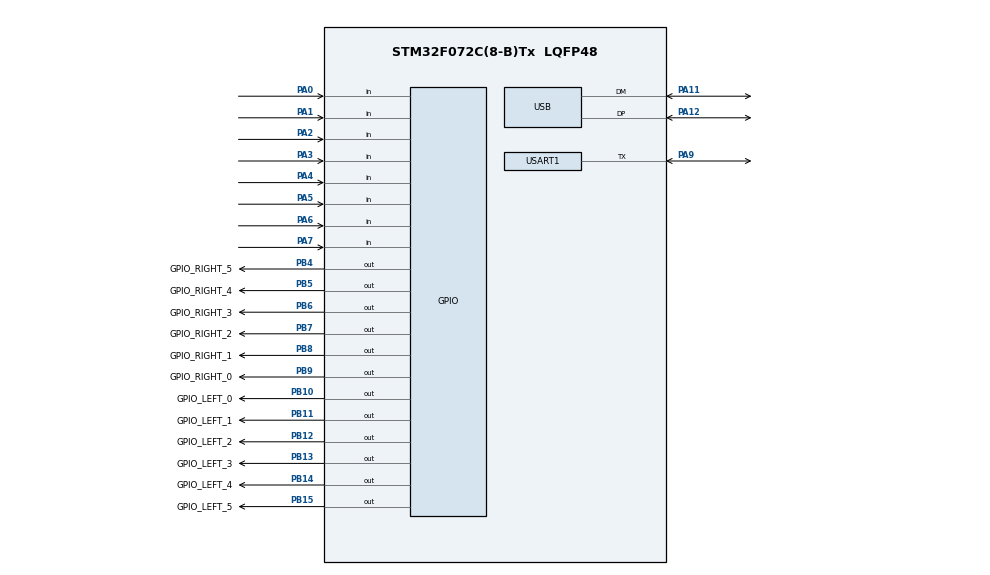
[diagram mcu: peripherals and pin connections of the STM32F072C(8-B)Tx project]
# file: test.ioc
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CRC.InputDataFormat=CRC_INPUTDATA_FORMAT_BYTES
Dma.Request0=USART1_TX
Dma.Request1=USART1_RX
Dma.USART1_RX.1.Direction=DMA_PERIPH_TO_MEMORY
Dma.USART1_RX.1.Instance=DMA1_Channel3
Dma.USART1_RX.1.MemDataAlignment=DMA_MDATAALIGN_BYTE
Dma.USART1_RX.1.MemInc=DMA_MINC_ENABLE
Dma.USART1_RX.1.Mode=DMA_NORMAL
Dma.USART1_RX.1.PeriphDataAlignment=DMA_PDATAALIGN_BYTE
Dma.USART1_RX.1.PeriphInc=DMA_PINC_DISABLE
Dma.USART1_RX.1.Priority=DMA_PRIORITY_VERY_HIGH
Dma.USART1_TX.0.Direction=DMA_MEMORY_TO_PERIPH
Dma.USART1_TX.0.Instance=DMA1_Channel4
Dma.USART1_TX.0.MemDataAlignment=DMA_MDATAALIGN_BYTE
Dma.USART1_TX.0.MemInc=DMA_MINC_ENABLE
Dma.USART1_TX.0.Mode=DMA_NORMAL
Dma.USART1_TX.0.PeriphDataAlignment=DMA_PDATAALIGN_BYTE
Dma.USART1_TX.0.PeriphInc=DMA_PINC_DISABLE
Dma.USART1_TX.0.Priority=DMA_PRIORITY_HIGH
Mcu.Family=STM32F0
Mcu.Name=STM32F072C(8-B)Tx
Mcu.Package=LQFP48
NVIC.DMA1_Channel2_3_IRQn=true\:0\:0\:false\:false\:true\:false\:true
NVIC.DMA1_Channel4_5_6_7_IRQn=true\:0\:0\:false\:false\:true\:false\:true
NVIC.TIM15_IRQn=true\:0\:0\:false\:false\:false\:true\:false
NVIC.TIM16_IRQn=true\:0\:0\:false\:false\:false\:true\:false
NVIC.TIM17_IRQn=true\:0\:0\:false\:false\:false\:true\:false
NVIC.TIM6_DAC_IRQn=true\:0\:0\:false\:false\:false\:true\:false
NVIC.TIM7_IRQn=true\:0\:0\:false\:false\:false\:true\:false
NVIC.USART1_IRQn=true\:0\:0\:false\:false\:true\:true\:true
NVIC.USB_IRQn=true\:0\:0\:false\:false\:true\:false\:true
PA0.GPIO_PuPd=GPIO_PULLDOWN
PA0.Signal=GPIO_Input
PA1.GPIO_PuPd=GPIO_PULLDOWN
PA1.Signal=GPIO_Input
PA11.Mode=Device
PA11.Signal=USB_DM
PA12.Mode=Device
PA12.Signal=USB_DP
PA13.Mode=Serial_Wire
PA13.Signal=SYS_SWDIO
PA14.Mode=Serial_Wire
PA14.Signal=SYS_SWCLK
PA2.GPIO_PuPd=GPIO_PULLDOWN
PA2.Signal=GPIO_Input
PA3.GPIO_PuPd=GPIO_PULLDOWN
PA3.Signal=GPIO_Input
PA4.GPIO_PuPd=GPIO_PULLDOWN
PA4.Signal=GPIO_Input
PA5.GPIO_PuPd=GPIO_PULLDOWN
PA5.Signal=GPIO_Input
PA6.GPIO_PuPd=GPIO_PULLDOWN
PA6.Signal=GPIO_Input
PA7.GPIO_PuPd=GPIO_PULLDOWN
PA7.Signal=GPIO_Input
PA9.GPIO_ModeDefaultOD=GPIO_MODE_AF_OD
PA9.GPIO_PuPdOD=GPIO_NOPULL
PA9.GPIO_Speed=GPIO_SPEED_FREQ_LOW
PA9.Mode=Half_duplex(single_wire_mode)
PA9.Signal=USART1_TX
PB10.GPIO_Label=GPIO_LEFT_0
PB10.GPIO_ModeDefaultOutputPP=GPIO_MODE_OUTPUT_PP
PB10.GPIO_Speed=GPIO_SPEED_FREQ_LOW
PB10.Signal=GPIO_Output
PB11.GPIO_Label=GPIO_LEFT_1
PB11.GPIO_ModeDefaultOutputPP=GPIO_MODE_OUTPUT_PP
PB11.GPIO_Speed=GPIO_SPEED_FREQ_LOW
PB11.Signal=GPIO_Output
PB12.GPIO_Label=GPIO_LEFT_2
PB12.GPIO_ModeDefaultOutputPP=GPIO_MODE_OUTPUT_PP
PB12.GPIO_Speed=GPIO_SPEED_FREQ_LOW
PB12.Signal=GPIO_Output
PB13.GPIO_Label=GPIO_LEFT_3
PB13.GPIO_ModeDefaultOutputPP=GPIO_MODE_OUTPUT_PP
PB13.GPIO_Speed=GPIO_SPEED_FREQ_LOW
PB13.Signal=GPIO_Output
PB14.GPIO_Label=GPIO_LEFT_4
PB14.GPIO_ModeDefaultOutputPP=GPIO_MODE_OUTPUT_PP
PB14.GPIO_Speed=GPIO_SPEED_FREQ_LOW
PB14.Signal=GPIO_Output
PB15.GPIO_Label=GPIO_LEFT_5
PB15.GPIO_ModeDefaultOutputPP=GPIO_MODE_OUTPUT_PP
PB15.GPIO_Speed=GPIO_SPEED_FREQ_LOW
PB15.Signal=GPIO_Output
PB4.GPIO_Label=GPIO_RIGHT_5
PB4.GPIO_Speed=GPIO_SPEED_FREQ_LOW
PB4.Signal=GPIO_Output
PB5.GPIO_Label=GPIO_RIGHT_4
PB5.GPIO_Speed=GPIO_SPEED_FREQ_LOW
PB5.Signal=GPIO_Output
PB6.GPIO_Label=GPIO_RIGHT_3
PB6.GPIO_Speed=GPIO_SPEED_FREQ_LOW
PB6.Signal=GPIO_Output
PB7.GPIO_Label=GPIO_RIGHT_2
PB7.GPIO_Speed=GPIO_SPEED_FREQ_LOW
PB7.Signal=GPIO_Output
PB8.GPIO_Label=GPIO_RIGHT_1
PB8.GPIO_Speed=GPIO_SPEED_FREQ_LOW
PB8.Signal=GPIO_Output
PB9.GPIO_Label=GPIO_RIGHT_0
PB9.GPIO_Speed=GPIO_SPEED_FREQ_LOW
PB9.Signal=GPIO_Output
ProjectManager.HeapSize=0x200
ProjectManager.StackSize=0x400
ProjectManager.TargetToolchain=Makefile
RCC.AHBFreq_Value=16000000
RCC.APB1Freq_Value=16000000
RCC.APB1TimFreq_Value=16000000
RCC.HCLKFreq_Value=16000000
RCC.HSI48CalibrationValue=32
RCC.PLLDivider=RCC_PREDIV_DIV6
RCC.PLLSourceVirtual=RCC_PLLSOURCE_HSI48
RCC.RCC_MCOSource=RCC_MCO1SOURCE_HSI48
RCC.SYSCLKFreq_VALUE=16000000
RCC.SYSCLKSource=RCC_SYSCLKSOURCE_PLLCLK
TIM15.Period=500
TIM15.Prescaler=15999
TIM16.Period=99
TIM16.Prescaler=15999
TIM17.Period=500
TIM17.Prescaler=15999
TIM6.Period=500
TIM6.Prescaler=15
TIM6.TIM_MasterOutputTrigger=TIM_TRGO_RESET
TIM7.Period=9
TIM7.Prescaler=15999
USART1.AutoBaudRateEnableParam=UART_ADVFEATURE_AUTOBAUDRATE_DISABLE
USART1.BaudRate=1000000
USART1.DMADisableonRxErrorParam=ADVFEATURE_DMA_ENABLEONRXERROR
USART1.Mode=MODE_TX_RX
USART1.OverSampling=UART_OVERSAMPLING_16
USART1.OverrunDisableParam=ADVFEATURE_OVERRUN_ENABLE
USART1.SwapParam=ADVFEATURE_SWAP_DISABLE
USART1.VirtualMode-Half_duplex(single_wire_mode)=VM_ASYNC
USB.low_power_enable=DISABLE
USB.lpm_enable=ENABLE
USB_DEVICE.CLASS_NAME_FS=CUSTOM_HID
USB_DEVICE.CUSTOM_HID_FS_BINTERVAL=0x1
USB_DEVICE.MANUFACTURER_STRING=bareminimum
USB_DEVICE.PRODUCT_STRING_CUSTOMHID_FS=bareminimum keys
USB_DEVICE.USBD_CUSTOMHID_OUTREPORT_BUF_SIZE=8
USB_DEVICE.USBD_CUSTOM_HID_REPORT_DESC_SIZE=41
USB_DEVICE.USBD_SELF_POWERED=0
USB_DEVICE.VirtualMode=CustomHid
USB_DEVICE.VirtualModeFS=Custom_Hid_FS
VP_CRC_VS_CRC.Mode=CRC_Activate
VP_RCC_USB.Mode=CRS SYNC Source USB
VP_TIM15_VS_OPM.Mode=OPM_bit
VP_TIM16_VS_ClockSourceINT.Mode=Enable_Timer
VP_TIM16_VS_OPM.Mode=OPM_bit
VP_TIM17_VS_ClockSourceINT.Mode=Enable_Timer
VP_TIM17_VS_OPM.Mode=OPM_bit
VP_TIM6_VS_ClockSourceINT.Mode=Enable_Timer
VP_TIM6_VS_OPM.Mode=OPM_bit
VP_TIM7_VS_ClockSourceINT.Mode=Enable_Timer
VP_TIM7_VS_OPM.Mode=OPM_bit
VP_USB_DEVICE_VS_USB_DEVICE_CUSTOM_HID_FS.Mode=CUSTOM_HID_FS
board=custom

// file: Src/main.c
/* USER CODE BEGIN Header */
/**
  ******************************************************************************
  * @file           : main.c
  * @brief          : Main program body
  ******************************************************************************
  * @attention
  *
  * <h2><center>&copy; Copyright (c) 2020 STMicroelectronics.
  * All rights reserved.</center></h2>
  *
  * This software component is licensed by ST under Ultimate Liberty license
  * SLA0044, the "License"; You may not use this file except in compliance with
  * the License. You may obtain a copy of the License at:
  *                             www.st.com/SLA0044
  *
  ******************************************************************************
  */
/* USER CODE END Header */

#include "main.h"
#include "usb_device.h"

/* USER CODE BEGIN Includes */

#include "app.h"

/* USER CODE END Includes */

UART_HandleTypeDef huart1;
DMA_HandleTypeDef hdma_usart1_tx;
DMA_HandleTypeDef hdma_usart1_rx;

void SystemClock_Config(void);
static void MX_GPIO_Init(void);
static void MX_DMA_Init(void);
static void MX_USART1_UART_Init(void);
static void MX_TIM6_Init(void);
static void MX_TIM7_Init(void);
static void MX_TIM16_Init(void);
static void MX_TIM17_Init(void);
static void MX_CRC_Init(void);
static void MX_TIM15_Init(void);

int main(void)
{

  /* MCU Configuration--------------------------------------------------------*/

  /* Reset of all peripherals, Initializes the Flash interface and the Systick. */
  HAL_Init();

  /* Configure the system clock */
  SystemClock_Config();

  /* Initialize all configured peripherals */
  MX_GPIO_Init();
  MX_DMA_Init();
  MX_USART1_UART_Init();
  MX_USB_DEVICE_Init();
  MX_TIM6_Init();
  MX_TIM7_Init();
  MX_TIM16_Init();
  MX_TIM17_Init();
  MX_CRC_Init();
  MX_TIM15_Init();
  /* USER CODE BEGIN 2 */
  app();
  /* USER CODE END 2 */

  /* Infinite loop */
  while (1)
  {

  }
}

void SystemClock_Config(void)
{
  LL_FLASH_SetLatency(LL_FLASH_LATENCY_0);

  if(LL_FLASH_GetLatency() != LL_FLASH_LATENCY_0)
  {
  Error_Handler();
  }
  LL_RCC_HSI48_Enable();

   /* Wait till HSI48 is ready */
  while(LL_RCC_HSI48_IsReady() != 1)
  {

  }
  LL_RCC_PLL_ConfigDomain_SYS(LL_RCC_PLLSOURCE_HSI48, LL_RCC_PLL_MUL_2, LL_RCC_PREDIV_DIV_6);
  LL_RCC_PLL_Enable();

   /* Wait till PLL is ready */
  while(LL_RCC_PLL_IsReady() != 1)
  {

  }
  LL_RCC_SetAHBPrescaler(LL_RCC_SYSCLK_DIV_1);
  LL_RCC_SetAPB1Prescaler(LL_RCC_APB1_DIV_1);
  LL_RCC_SetSysClkSource(LL_RCC_SYS_CLKSOURCE_PLL);

   /* Wait till System clock is ready */
  while(LL_RCC_GetSysClkSource() != LL_RCC_SYS_CLKSOURCE_STATUS_PLL)
  {

  }
  LL_SetSystemCoreClock(16000000);

   /* Update the time base */
  if (HAL_InitTick (TICK_INT_PRIORITY) != HAL_OK)
  {
    Error_Handler();
  };
  LL_RCC_SetUSARTClockSource(LL_RCC_USART1_CLKSOURCE_PCLK1);
  LL_RCC_SetUSBClockSource(LL_RCC_USB_CLKSOURCE_HSI48);
  LL_CRS_SetSyncDivider(LL_CRS_SYNC_DIV_1);
  LL_CRS_SetSyncPolarity(LL_CRS_SYNC_POLARITY_RISING);
  LL_CRS_SetSyncSignalSource(LL_CRS_SYNC_SOURCE_USB);
  LL_CRS_SetFreqErrorLimit(34);
  LL_CRS_SetHSI48SmoothTrimming(32);
}

static void MX_CRC_Init(void)
{

  /* Peripheral clock enable */
  LL_AHB1_GRP1_EnableClock(LL_AHB1_GRP1_PERIPH_CRC);

  LL_CRC_SetInputDataReverseMode(CRC, LL_CRC_INDATA_REVERSE_NONE);
  LL_CRC_SetOutputDataReverseMode(CRC, LL_CRC_OUTDATA_REVERSE_NONE);
  LL_CRC_SetInitialData(CRC, LL_CRC_DEFAULT_CRC_INITVALUE);

}

static void MX_TIM6_Init(void)
{

  LL_TIM_InitTypeDef TIM_InitStruct = {0};

  /* Peripheral clock enable */
  LL_APB1_GRP1_EnableClock(LL_APB1_GRP1_PERIPH_TIM6);

  /* TIM6 interrupt Init */
  NVIC_SetPriority(TIM6_DAC_IRQn, 0);
  NVIC_EnableIRQ(TIM6_DAC_IRQn);

  TIM_InitStruct.Prescaler = 15;
  TIM_InitStruct.CounterMode = LL_TIM_COUNTERMODE_UP;
  TIM_InitStruct.Autoreload = 500;
  LL_TIM_Init(TIM6, &TIM_InitStruct);
  LL_TIM_DisableARRPreload(TIM6);
  LL_TIM_SetOnePulseMode(TIM6, LL_TIM_ONEPULSEMODE_SINGLE);
  LL_TIM_SetTriggerOutput(TIM6, LL_TIM_TRGO_RESET);
  LL_TIM_DisableMasterSlaveMode(TIM6);

}

static void MX_TIM7_Init(void)
{

  LL_TIM_InitTypeDef TIM_InitStruct = {0};

  /* Peripheral clock enable */
  LL_APB1_GRP1_EnableClock(LL_APB1_GRP1_PERIPH_TIM7);

  /* TIM7 interrupt Init */
  NVIC_SetPriority(TIM7_IRQn, 0);
  NVIC_EnableIRQ(TIM7_IRQn);

  TIM_InitStruct.Prescaler = 15999;
  TIM_InitStruct.CounterMode = LL_TIM_COUNTERMODE_UP;
  TIM_InitStruct.Autoreload = 9;
  LL_TIM_Init(TIM7, &TIM_InitStruct);
  LL_TIM_DisableARRPreload(TIM7);
  LL_TIM_SetOnePulseMode(TIM7, LL_TIM_ONEPULSEMODE_SINGLE);
  LL_TIM_SetTriggerOutput(TIM7, LL_TIM_TRGO_RESET);
  LL_TIM_DisableMasterSlaveMode(TIM7);

}

static void MX_TIM15_Init(void)
{

  LL_TIM_InitTypeDef TIM_InitStruct = {0};

  /* Peripheral clock enable */
  LL_APB1_GRP2_EnableClock(LL_APB1_GRP2_PERIPH_TIM15);

  /* TIM15 interrupt Init */
  NVIC_SetPriority(TIM15_IRQn, 0);
  NVIC_EnableIRQ(TIM15_IRQn);

  TIM_InitStruct.Prescaler = 15999;
  TIM_InitStruct.CounterMode = LL_TIM_COUNTERMODE_UP;
  TIM_InitStruct.Autoreload = 500;
  TIM_InitStruct.ClockDivision = LL_TIM_CLOCKDIVISION_DIV1;
  TIM_InitStruct.RepetitionCounter = 0;
  LL_TIM_Init(TIM15, &TIM_InitStruct);
  LL_TIM_DisableARRPreload(TIM15);
  LL_TIM_SetOnePulseMode(TIM15, LL_TIM_ONEPULSEMODE_SINGLE);

}

static void MX_TIM16_Init(void)
{

  LL_TIM_InitTypeDef TIM_InitStruct = {0};

  /* Peripheral clock enable */
  LL_APB1_GRP2_EnableClock(LL_APB1_GRP2_PERIPH_TIM16);

  /* TIM16 interrupt Init */
  NVIC_SetPriority(TIM16_IRQn, 0);
  NVIC_EnableIRQ(TIM16_IRQn);

  TIM_InitStruct.Prescaler = 15999;
  TIM_InitStruct.CounterMode = LL_TIM_COUNTERMODE_UP;
  TIM_InitStruct.Autoreload = 99;
  TIM_InitStruct.ClockDivision = LL_TIM_CLOCKDIVISION_DIV1;
  TIM_InitStruct.RepetitionCounter = 0;
  LL_TIM_Init(TIM16, &TIM_InitStruct);
  LL_TIM_DisableARRPreload(TIM16);
  LL_TIM_SetOnePulseMode(TIM16, LL_TIM_ONEPULSEMODE_SINGLE);

}

static void MX_TIM17_Init(void)
{

  LL_TIM_InitTypeDef TIM_InitStruct = {0};

  /* Peripheral clock enable */
  LL_APB1_GRP2_EnableClock(LL_APB1_GRP2_PERIPH_TIM17);

  /* TIM17 interrupt Init */
  NVIC_SetPriority(TIM17_IRQn, 0);
  NVIC_EnableIRQ(TIM17_IRQn);

  TIM_InitStruct.Prescaler = 15999;
  TIM_InitStruct.CounterMode = LL_TIM_COUNTERMODE_UP;
  TIM_InitStruct.Autoreload = 500;
  TIM_InitStruct.ClockDivision = LL_TIM_CLOCKDIVISION_DIV1;
  TIM_InitStruct.RepetitionCounter = 0;
  LL_TIM_Init(TIM17, &TIM_InitStruct);
  LL_TIM_DisableARRPreload(TIM17);
  LL_TIM_SetOnePulseMode(TIM17, LL_TIM_ONEPULSEMODE_SINGLE);

}

static void MX_USART1_UART_Init(void)
{

  huart1.Instance = USART1;
  huart1.Init.BaudRate = 1000000;
  huart1.Init.WordLength = UART_WORDLENGTH_8B;
  huart1.Init.StopBits = UART_STOPBITS_1;
  huart1.Init.Parity = UART_PARITY_NONE;
  huart1.Init.Mode = UART_MODE_TX_RX;
  huart1.Init.HwFlowCtl = UART_HWCONTROL_NONE;
  huart1.Init.OverSampling = UART_OVERSAMPLING_16;
  huart1.Init.OneBitSampling = UART_ONE_BIT_SAMPLE_DISABLE;
  huart1.AdvancedInit.AdvFeatureInit = UART_ADVFEATURE_NO_INIT;
  if (HAL_HalfDuplex_Init(&huart1) != HAL_OK)
  {
    Error_Handler();
  }

}

static void MX_DMA_Init(void)
{

  /* Init with LL driver */
  /* DMA controller clock enable */
  LL_AHB1_GRP1_EnableClock(LL_AHB1_GRP1_PERIPH_DMA1);

  /* DMA interrupt init */
  /* DMA1_Channel2_3_IRQn interrupt configuration */
  HAL_NVIC_SetPriority(DMA1_Channel2_3_IRQn, 0, 0);
  HAL_NVIC_EnableIRQ(DMA1_Channel2_3_IRQn);
  /* DMA1_Channel4_5_6_7_IRQn interrupt configuration */
  HAL_NVIC_SetPriority(DMA1_Channel4_5_6_7_IRQn, 0, 0);
  HAL_NVIC_EnableIRQ(DMA1_Channel4_5_6_7_IRQn);

}

static void MX_GPIO_Init(void)
{
  LL_GPIO_InitTypeDef GPIO_InitStruct = {0};

  /* GPIO Ports Clock Enable */
  LL_AHB1_GRP1_EnableClock(LL_AHB1_GRP1_PERIPH_GPIOC);
  LL_AHB1_GRP1_EnableClock(LL_AHB1_GRP1_PERIPH_GPIOF);
  LL_AHB1_GRP1_EnableClock(LL_AHB1_GRP1_PERIPH_GPIOA);
  LL_AHB1_GRP1_EnableClock(LL_AHB1_GRP1_PERIPH_GPIOB);

  /**/
  LL_GPIO_ResetOutputPin(GPIO_LEFT_0_GPIO_Port, GPIO_LEFT_0_Pin);

  /**/
  LL_GPIO_ResetOutputPin(GPIO_LEFT_1_GPIO_Port, GPIO_LEFT_1_Pin);

  /**/
  LL_GPIO_ResetOutputPin(GPIO_LEFT_2_GPIO_Port, GPIO_LEFT_2_Pin);

  /**/
  LL_GPIO_ResetOutputPin(GPIO_LEFT_3_GPIO_Port, GPIO_LEFT_3_Pin);

  /**/
  LL_GPIO_ResetOutputPin(GPIO_LEFT_4_GPIO_Port, GPIO_LEFT_4_Pin);

  /**/
  LL_GPIO_ResetOutputPin(GPIO_LEFT_5_GPIO_Port, GPIO_LEFT_5_Pin);

  /**/
  LL_GPIO_ResetOutputPin(GPIO_RIGHT_5_GPIO_Port, GPIO_RIGHT_5_Pin);

  /**/
  LL_GPIO_ResetOutputPin(GPIO_RIGHT_4_GPIO_Port, GPIO_RIGHT_4_Pin);

  /**/
  LL_GPIO_ResetOutputPin(GPIO_RIGHT_3_GPIO_Port, GPIO_RIGHT_3_Pin);

  /**/
  LL_GPIO_ResetOutputPin(GPIO_RIGHT_2_GPIO_Port, GPIO_RIGHT_2_Pin);

  /**/
  LL_GPIO_ResetOutputPin(GPIO_RIGHT_1_GPIO_Port, GPIO_RIGHT_1_Pin);

  /**/
  LL_GPIO_ResetOutputPin(GPIO_RIGHT_0_GPIO_Port, GPIO_RIGHT_0_Pin);

  /**/
  GPIO_InitStruct.Pin = LL_GPIO_PIN_13;
  GPIO_InitStruct.Mode = LL_GPIO_MODE_ANALOG;
  GPIO_InitStruct.Pull = LL_GPIO_PULL_NO;
  LL_GPIO_Init(GPIOC, &GPIO_InitStruct);

  /**/
  GPIO_InitStruct.Pin = LL_GPIO_PIN_14;
  GPIO_InitStruct.Mode = LL_GPIO_MODE_ANALOG;
  GPIO_InitStruct.Pull = LL_GPIO_PULL_NO;
  LL_GPIO_Init(GPIOC, &GPIO_InitStruct);

  /**/
  GPIO_InitStruct.Pin = LL_GPIO_PIN_15;
  GPIO_InitStruct.Mode = LL_GPIO_MODE_ANALOG;
  GPIO_InitStruct.Pull = LL_GPIO_PULL_NO;
  LL_GPIO_Init(GPIOC, &GPIO_InitStruct);

  /**/
  GPIO_InitStruct.Pin = LL_GPIO_PIN_0;
  GPIO_InitStruct.Mode = LL_GPIO_MODE_ANALOG;
  GPIO_InitStruct.Pull = LL_GPIO_PULL_NO;
  LL_GPIO_Init(GPIOF, &GPIO_InitStruct);

  /**/
  GPIO_InitStruct.Pin = LL_GPIO_PIN_1;
  GPIO_InitStruct.Mode = LL_GPIO_MODE_ANALOG;
  GPIO_InitStruct.Pull = LL_GPIO_PULL_NO;
  LL_GPIO_Init(GPIOF, &GPIO_InitStruct);

  /**/
  GPIO_InitStruct.Pin = LL_GPIO_PIN_0;
  GPIO_InitStruct.Mode = LL_GPIO_MODE_INPUT;
  GPIO_InitStruct.Pull = LL_GPIO_PULL_DOWN;
  LL_GPIO_Init(GPIOA, &GPIO_InitStruct);

  /**/
  GPIO_InitStruct.Pin = LL_GPIO_PIN_1;
  GPIO_InitStruct.Mode = LL_GPIO_MODE_INPUT;
  GPIO_InitStruct.Pull = LL_GPIO_PULL_DOWN;
  LL_GPIO_Init(GPIOA, &GPIO_InitStruct);

  /**/
  GPIO_InitStruct.Pin = LL_GPIO_PIN_2;
  GPIO_InitStruct.Mode = LL_GPIO_MODE_INPUT;
  GPIO_InitStruct.Pull = LL_GPIO_PULL_DOWN;
  LL_GPIO_Init(GPIOA, &GPIO_InitStruct);

  /**/
  GPIO_InitStruct.Pin = LL_GPIO_PIN_3;
  GPIO_InitStruct.Mode = LL_GPIO_MODE_INPUT;
  GPIO_InitStruct.Pull = LL_GPIO_PULL_DOWN;
  LL_GPIO_Init(GPIOA, &GPIO_InitStruct);

  /**/
  GPIO_InitStruct.Pin = LL_GPIO_PIN_4;
  GPIO_InitStruct.Mode = LL_GPIO_MODE_INPUT;
  GPIO_InitStruct.Pull = LL_GPIO_PULL_DOWN;
  LL_GPIO_Init(GPIOA, &GPIO_InitStruct);

  /**/
  GPIO_InitStruct.Pin = LL_GPIO_PIN_5;
  GPIO_InitStruct.Mode = LL_GPIO_MODE_INPUT;
  GPIO_InitStruct.Pull = LL_GPIO_PULL_DOWN;
  LL_GPIO_Init(GPIOA, &GPIO_InitStruct);

  /**/
  GPIO_InitStruct.Pin = LL_GPIO_PIN_6;
  GPIO_InitStruct.Mode = LL_GPIO_MODE_INPUT;
  GPIO_InitStruct.Pull = LL_GPIO_PULL_DOWN;
  LL_GPIO_Init(GPIOA, &GPIO_InitStruct);

  /**/
  GPIO_InitStruct.Pin = LL_GPIO_PIN_7;
  GPIO_InitStruct.Mode = LL_GPIO_MODE_INPUT;
  GPIO_InitStruct.Pull = LL_GPIO_PULL_DOWN;
  LL_GPIO_Init(GPIOA, &GPIO_InitStruct);

  /**/
  GPIO_InitStruct.Pin = LL_GPIO_PIN_0;
  GPIO_InitStruct.Mode = LL_GPIO_MODE_ANALOG;
  GPIO_InitStruct.Pull = LL_GPIO_PULL_NO;
  LL_GPIO_Init(GPIOB, &GPIO_InitStruct);

  /**/
  GPIO_InitStruct.Pin = LL_GPIO_PIN_1;
  GPIO_InitStruct.Mode = LL_GPIO_MODE_ANALOG;
  GPIO_InitStruct.Pull = LL_GPIO_PULL_NO;
  LL_GPIO_Init(GPIOB, &GPIO_InitStruct);

  /**/
  GPIO_InitStruct.Pin = LL_GPIO_PIN_2;
  GPIO_InitStruct.Mode = LL_GPIO_MODE_ANALOG;
  GPIO_InitStruct.Pull = LL_GPIO_PULL_NO;
  LL_GPIO_Init(GPIOB, &GPIO_InitStruct);

  /**/
  GPIO_InitStruct.Pin = GPIO_LEFT_0_Pin;
  GPIO_InitStruct.Mode = LL_GPIO_MODE_OUTPUT;
  GPIO_InitStruct.Speed = LL_GPIO_SPEED_FREQ_LOW;
  GPIO_InitStruct.OutputType = LL_GPIO_OUTPUT_PUSHPULL;
  GPIO_InitStruct.Pull = LL_GPIO_PULL_NO;
  LL_GPIO_Init(GPIO_LEFT_0_GPIO_Port, &GPIO_InitStruct);

  /**/
  GPIO_InitStruct.Pin = GPIO_LEFT_1_Pin;
  GPIO_InitStruct.Mode = LL_GPIO_MODE_OUTPUT;
  GPIO_InitStruct.Speed = LL_GPIO_SPEED_FREQ_LOW;
  GPIO_InitStruct.OutputType = LL_GPIO_OUTPUT_PUSHPULL;
  GPIO_InitStruct.Pull = LL_GPIO_PULL_NO;
  LL_GPIO_Init(GPIO_LEFT_1_GPIO_Port, &GPIO_InitStruct);

  /**/
  GPIO_InitStruct.Pin = GPIO_LEFT_2_Pin;
  GPIO_InitStruct.Mode = LL_GPIO_MODE_OUTPUT;
  GPIO_InitStruct.Speed = LL_GPIO_SPEED_FREQ_LOW;
  GPIO_InitStruct.OutputType = LL_GPIO_OUTPUT_PUSHPULL;
  GPIO_InitStruct.Pull = LL_GPIO_PULL_NO;
  LL_GPIO_Init(GPIO_LEFT_2_GPIO_Port, &GPIO_InitStruct);

  /**/
  GPIO_InitStruct.Pin = GPIO_LEFT_3_Pin;
  GPIO_InitStruct.Mode = LL_GPIO_MODE_OUTPUT;
  GPIO_InitStruct.Speed = LL_GPIO_SPEED_FREQ_LOW;
  GPIO_InitStruct.OutputType = LL_GPIO_OUTPUT_PUSHPULL;
  GPIO_InitStruct.Pull = LL_GPIO_PULL_NO;
  LL_GPIO_Init(GPIO_LEFT_3_GPIO_Port, &GPIO_InitStruct);

  /**/
  GPIO_InitStruct.Pin = GPIO_LEFT_4_Pin;
  GPIO_InitStruct.Mode = LL_GPIO_MODE_OUTPUT;
  GPIO_InitStruct.Speed = LL_GPIO_SPEED_FREQ_LOW;
  GPIO_InitStruct.OutputType = LL_GPIO_OUTPUT_PUSHPULL;
  GPIO_InitStruct.Pull = LL_GPIO_PULL_NO;
  LL_GPIO_Init(GPIO_LEFT_4_GPIO_Port, &GPIO_InitStruct);

  /**/
  GPIO_InitStruct.Pin = GPIO_LEFT_5_Pin;
  GPIO_InitStruct.Mode = LL_GPIO_MODE_OUTPUT;
  GPIO_InitStruct.Speed = LL_GPIO_SPEED_FREQ_LOW;
  GPIO_InitStruct.OutputType = LL_GPIO_OUTPUT_PUSHPULL;
  GPIO_InitStruct.Pull = LL_GPIO_PULL_NO;
  LL_GPIO_Init(GPIO_LEFT_5_GPIO_Port, &GPIO_InitStruct);

  /**/
  GPIO_InitStruct.Pin = LL_GPIO_PIN_8;
  GPIO_InitStruct.Mode = LL_GPIO_MODE_ANALOG;
  GPIO_InitStruct.Pull = LL_GPIO_PULL_NO;
  LL_GPIO_Init(GPIOA, &GPIO_InitStruct);

  /**/
  GPIO_InitStruct.Pin = LL_GPIO_PIN_10;
  GPIO_InitStruct.Mode = LL_GPIO_MODE_ANALOG;
  GPIO_InitStruct.Pull = LL_GPIO_PULL_NO;
  LL_GPIO_Init(GPIOA, &GPIO_InitStruct);

  /**/
  GPIO_InitStruct.Pin = LL_GPIO_PIN_15;
  GPIO_InitStruct.Mode = LL_GPIO_MODE_ANALOG;
  GPIO_InitStruct.Pull = LL_GPIO_PULL_NO;
  LL_GPIO_Init(GPIOA, &GPIO_InitStruct);

  /**/
  GPIO_InitStruct.Pin = LL_GPIO_PIN_3;
  GPIO_InitStruct.Mode = LL_GPIO_MODE_ANALOG;
  GPIO_InitStruct.Pull = LL_GPIO_PULL_NO;
  LL_GPIO_Init(GPIOB, &GPIO_InitStruct);

  /**/
  GPIO_InitStruct.Pin = GPIO_RIGHT_5_Pin;
  GPIO_InitStruct.Mode = LL_GPIO_MODE_OUTPUT;
  GPIO_InitStruct.Speed = LL_GPIO_SPEED_FREQ_LOW;
  GPIO_InitStruct.OutputType = LL_GPIO_OUTPUT_PUSHPULL;
  GPIO_InitStruct.Pull = LL_GPIO_PULL_NO;
  LL_GPIO_Init(GPIO_RIGHT_5_GPIO_Port, &GPIO_InitStruct);

  /**/
  GPIO_InitStruct.Pin = GPIO_RIGHT_4_Pin;
  GPIO_InitStruct.Mode = LL_GPIO_MODE_OUTPUT;
  GPIO_InitStruct.Speed = LL_GPIO_SPEED_FREQ_LOW;
  GPIO_InitStruct.OutputType = LL_GPIO_OUTPUT_PUSHPULL;
  GPIO_InitStruct.Pull = LL_GPIO_PULL_NO;
  LL_GPIO_Init(GPIO_RIGHT_4_GPIO_Port, &GPIO_InitStruct);

  /**/
  GPIO_InitStruct.Pin = GPIO_RIGHT_3_Pin;
  GPIO_InitStruct.Mode = LL_GPIO_MODE_OUTPUT;
  GPIO_InitStruct.Speed = LL_GPIO_SPEED_FREQ_LOW;
  GPIO_InitStruct.OutputType = LL_GPIO_OUTPUT_PUSHPULL;
  GPIO_InitStruct.Pull = LL_GPIO_PULL_NO;
  LL_GPIO_Init(GPIO_RIGHT_3_GPIO_Port, &GPIO_InitStruct);

  /**/
  GPIO_InitStruct.Pin = GPIO_RIGHT_2_Pin;
  GPIO_InitStruct.Mode = LL_GPIO_MODE_OUTPUT;
  GPIO_InitStruct.Speed = LL_GPIO_SPEED_FREQ_LOW;
  GPIO_InitStruct.OutputType = LL_GPIO_OUTPUT_PUSHPULL;
  GPIO_InitStruct.Pull = LL_GPIO_PULL_NO;
  LL_GPIO_Init(GPIO_RIGHT_2_GPIO_Port, &GPIO_InitStruct);

  /**/
  GPIO_InitStruct.Pin = GPIO_RIGHT_1_Pin;
  GPIO_InitStruct.Mode = LL_GPIO_MODE_OUTPUT;
  GPIO_InitStruct.Speed = LL_GPIO_SPEED_FREQ_LOW;
  GPIO_InitStruct.OutputType = LL_GPIO_OUTPUT_PUSHPULL;
  GPIO_InitStruct.Pull = LL_GPIO_PULL_NO;
  LL_GPIO_Init(GPIO_RIGHT_1_GPIO_Port, &GPIO_InitStruct);

  /**/
  GPIO_InitStruct.Pin = GPIO_RIGHT_0_Pin;
  GPIO_InitStruct.Mode = LL_GPIO_MODE_OUTPUT;
  GPIO_InitStruct.Speed = LL_GPIO_SPEED_FREQ_LOW;
  GPIO_InitStruct.OutputType = LL_GPIO_OUTPUT_PUSHPULL;
  GPIO_InitStruct.Pull = LL_GPIO_PULL_NO;
  LL_GPIO_Init(GPIO_RIGHT_0_GPIO_Port, &GPIO_InitStruct);

}

void Error_Handler(void)
{
}

/************************ (C) COPYRIGHT STMicroelectronics *****END OF FILE****/
